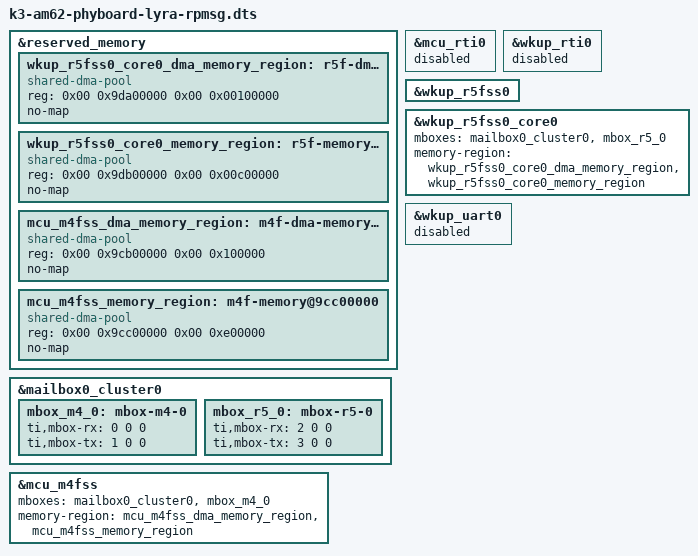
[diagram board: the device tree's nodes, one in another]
// SPDX-License-Identifier: GPL-2.0
/*
 * Copyright (C) 2022 PHYTEC Messtechnik GmbH
 * Author: Wadim Egorov <w.egorov@phytec.de>
 */

/dts-v1/;
/plugin/;

&reserved_memory {
	#address-cells = <2>;
	#size-cells = <2>;

	wkup_r5fss0_core0_dma_memory_region: r5f-dma-memory@9da00000 {
		compatible = "shared-dma-pool";
		reg = <0x00 0x9da00000 0x00 0x00100000>;
		no-map;
	};

	wkup_r5fss0_core0_memory_region: r5f-memory@9db00000 {
		compatible = "shared-dma-pool";
		reg = <0x00 0x9db00000 0x00 0x00c00000>;
		no-map;
	};

	mcu_m4fss_dma_memory_region: m4f-dma-memory@9cb00000 {
		compatible = "shared-dma-pool";
		reg = <0x00 0x9cb00000 0x00 0x100000>;
		no-map;
	};

	mcu_m4fss_memory_region: m4f-memory@9cc00000 {
		compatible = "shared-dma-pool";
		reg = <0x00 0x9cc00000 0x00 0xe00000>;
		no-map;
	};
};

&mailbox0_cluster0 {
	status = "okay";

	mbox_m4_0: mbox-m4-0 {
		ti,mbox-rx = <0 0 0>;
		ti,mbox-tx = <1 0 0>;
	};

	mbox_r5_0: mbox-r5-0 {
		ti,mbox-rx = <2 0 0>;
		ti,mbox-tx = <3 0 0>;
	};
};

&mcu_rti0 {
	/* MCU RTI0 is used by M4F firmware */
	status = "reserved";
};

&mcu_m4fss {
	status = "okay";
	mboxes = <&mailbox0_cluster0 &mbox_m4_0>;
	memory-region = <&mcu_m4fss_dma_memory_region>,
			<&mcu_m4fss_memory_region>;
};

&wkup_rti0 {
	/* WKUP RTI0 is used by DM firmware */
	status = "reserved";
};

&wkup_r5fss0 {
	status = "okay";
};

&wkup_r5fss0_core0 {
	status = "okay";
	mboxes = <&mailbox0_cluster0 &mbox_r5_0>;
	memory-region = <&wkup_r5fss0_core0_dma_memory_region>,
			<&wkup_r5fss0_core0_memory_region>;
};

&wkup_uart0 {
	/* WKUP UART0 is used by DM firmware */
	status = "reserved";
};
